# GD32W515 register map
File version: 1.0
CPU: CM33 r0p4, little endian, MPU, FPU, 4 interrupt priority bits
Registers are 32-bit, read-write, reset 0x0 unless marked. A register's access mark holds for its fields unless they carry their own. Offsets are from the block's base; [hi:lo] are bit positions.

## USART1 — Universal synchronous asynchronous receiver transmitter
Base 0x40004400
Same registers: SEC_USART1 0x50004400
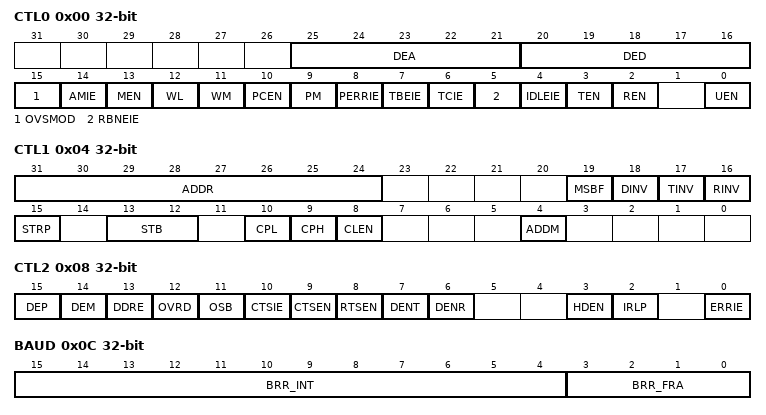
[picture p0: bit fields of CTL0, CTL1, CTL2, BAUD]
0x00 CTL0 — Control register 0
  [25:21] DEA — Driver Enable assertion time
  [20:16] DED — Driver Enable deassertion time
  [15] OVSMOD — Oversampling mode
  [14] AMIE — Character match interrupt enable
  [13] MEN — Mute mode enable
  [12] WL — Word length
  [11] WM — Receiver wakeup method
  [10] PCEN — Parity control enable
  [9] PM — Parity selection
  [8] PERRIE — PE interrupt enable
  [7] TBEIE — interrupt enable
  [6] TCIE — Transmission complete interrupt enable
  [5] RBNEIE — RXNE interrupt enable
  [4] IDLEIE — IDLE interrupt enable
  [3] TEN — Transmitter enable
  [2] REN — Receiver enable
  [0] UEN — USART enable
0x04 CTL1 — Control register 1
  [31:24] ADDR — Address of the USART terminal
  [19] MSBF — Most significant bit first
  [18] DINV — Data bit level inversion
  [17] TINV — TX pin active level inversion
  [16] RINV — RX pin active level inversion
  [15] STRP — Swap TX/RX pins
  [13:12] STB — STOP bits
  [10] CPL — Clock polarity
  [9] CPH — Clock phase
  [8] CLEN — Last bit clock pulse
  [4] ADDM — 7-bit Address Detection/4-bit Address Detection
0x08 CTL2 — Control register 2
  [15] DEP — Driver enable polarity selection
  [14] DEM — Driver enable mode
  [13] DDRE — DMA Disable on Reception Error
  [12] OVRD — Overrun Disable
  [11] OSB — One sample bit method enable
  [10] CTSIE — CTS interrupt enable
  [9] CTSEN — CTS enable
  [8] RTSEN — RTS enable
  [7] DENT — DMA enable transmitter
  [6] DENR — DMA enable receiver
  [3] HDEN — Half-duplex selection
  [2] IRLP — IrDA low-power
  [0] ERRIE — Error interrupt enable
0x0C BAUD — Baud rate register
  [15:4] BRR_INT — integer of baud-rate divider
  [3:0] BRR_FRA — integer of baud-rate divider
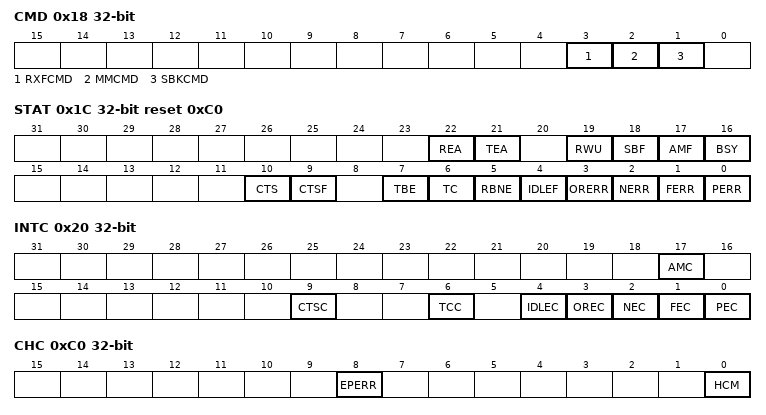
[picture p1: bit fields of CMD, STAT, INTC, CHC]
0x18 CMD wo — Command register
  [3] RXFCMD — Receive data flush request
  [2] MMCMD — Mute mode request
  [1] SBKCMD — Send break request
0x1C STAT ro reset 0xC0 — Interrupt & status register
  [22] REA — Receive enable acknowledge flag
  [21] TEA — Transmit enable acknowledge flag
  [19] RWU — Receiver wakeup from Mute mode
  [18] SBF — Send break flag
  [17] AMF — character match flag
  [16] BSY — Busy flag
  [10] CTS — CTS flag
  [9] CTSF — CTS interrupt flag
  [7] TBE — Transmit data register empty
  [6] TC — Transmission complete
  [5] RBNE — Read data register not empty
  [4] IDLEF — Idle line detected
  [3] ORERR — Overrun error
  [2] NERR — Noise detected flag
  [1] FERR — Framing error
  [0] PERR — Parity error
0x20 INTC wo — Interrupt flag clear register
  [17] AMC — Character match clear flag
  [9] CTSC — CTS clear flag
  [6] TCC — Transmission complete clear flag
  [4] IDLEC — Idle line detected clear flag
  [3] OREC — Overrun error clear flag
  [2] NEC — Noise detected clear flag
  [1] FEC — Frame error clear flag
  [0] PEC — Parity error clear flag
0x24 RDATA ro — Receive data register
  [8:0] RDATA — Receive data value
0x28 TDATA — Transmit data register
  [8:0] TDATA — Transmit data value
0xC0 CHC — coherence control register
  [8] EPERR — Early parity error flag
  [0] HCM — Hardware flow control coherence mode
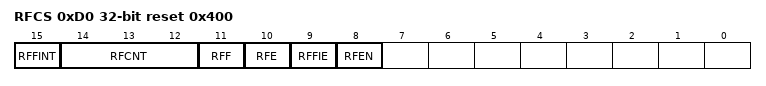
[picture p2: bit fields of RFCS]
0xD0 RFCS access per field reset 0x400 — USART receive FIFO control and status register
  [15] RFFINT rw — Receive FIFO full interrupt flag
  [14:12] RFCNT ro — Receive FIFO count number
  [11] RFF ro — Receive FIFO full flag
  [10] RFE ro — Receive FIFO empty flag
  [9] RFFIE rw — Receive FIFO full interrupt enable
  [8] RFEN rw — Receive FIFO enable

## WWDGT — Window watchdog timer
Base 0x40002C00
Same registers: SEC_WWDGT 0x50002C00
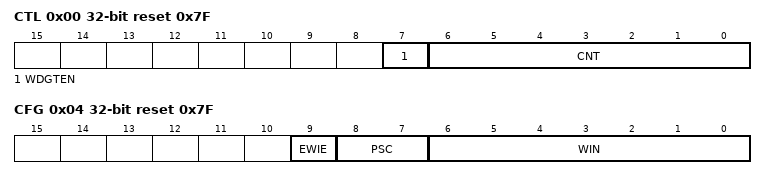
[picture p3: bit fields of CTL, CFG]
0x00 CTL reset 0x7F — Control register
  [7] WDGTEN — Activation bit
  [6:0] CNT — 7-bit counter
0x04 CFG reset 0x7F — Configuration register
  [9] EWIE — Early wakeup interrupt
  [8:7] PSC — Prescaler
  [6:0] WIN — 7-bit window value
0x08 STAT — Status register
  [0] EWIF — Early wakeup interrupt flag
